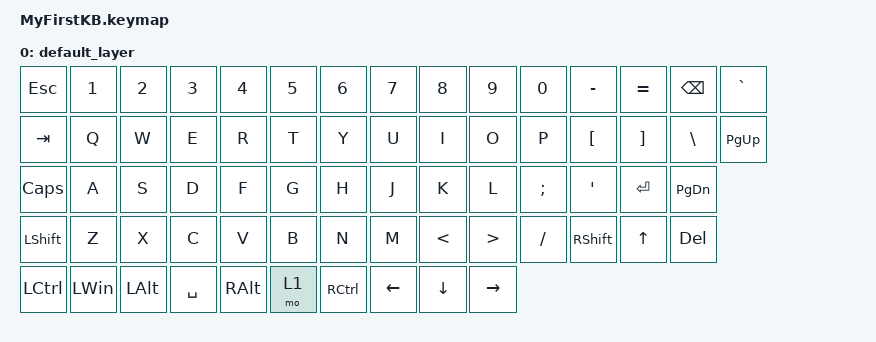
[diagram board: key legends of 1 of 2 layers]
#include <behaviors.dtsi>
#include <dt-bindings/zmk/keys.h>
#include <dt-bindings/zmk/bt.h>

/ {
    keymap {
        compatible = "zmk,keymap";

        default_layer {
            bindings = <
                &kp ESC          &kp NUMBER_1  &kp NUMBER_2 &kp NUMBER_3 &kp NUMBER_4  &kp NUMBER_5 &kp NUMBER_6      &kp NUMBER_7   &kp NUMBER_8   &kp NUMBER_9     &kp NUMBER_0  &kp MINUS       &kp EQUAL     &kp BACKSPACE &kp GRAVE
                &kp TAB          &kp Q         &kp W        &kp E        &kp R         &kp T        &kp Y             &kp U          &kp I          &kp O            &kp P         &kp LBKT        &kp RBKT      &kp BACKSLASH &kp PAGE_UP
                &kp CAPSLOCK     &kp A         &kp S        &kp D        &kp F         &kp G        &kp H             &kp J          &kp K          &kp L            &kp SEMICOLON &kp APOSTROPHE  &kp ENTER     &kp PAGE_DOWN
                &kp LEFT_SHIFT   &kp Z         &kp X        &kp C        &kp V         &kp B        &kp N             &kp M          &kp LESS_THAN  &kp GREATER_THAN &kp SLASH     &kp RIGHT_SHIFT &kp UP_ARROW  &kp DELETE
                &kp LEFT_CONTROL &kp LEFT_WIN  &kp LEFT_ALT &kp SPACE    &kp RIGHT_ALT &mo 1        &kp RIGHT_CONTROL &kp LEFT_ARROW &kp DOWN_ARROW &kp RIGHT_ARROW
            >;
        };

        bt_layer {
            bindings = <
                &bootloader      &bt BT_SEL 0     &bt BT_SEL 1     &bt BT_SEL 2
                &none                        
                &none            
                &none            &none            &none            &none            &none            &none            &none            &none            &none            &none            &none            &none            &none            &bt BT_CLR
                &none
            >;
        };
    };
};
